# STM8TL53F4 register map
Vendor: STMicroelectronics; Series: STM8T; File version: 1.0
CPU: other r1p0, big endian, no MPU, no FPU, 4 interrupt priority bits
Registers are 8-bit, read-write, reset 0x0 unless marked. A register's access mark holds for its fields unless they carry their own. Offsets are from the block's base; [hi:lo] are bit positions; {n}, {i} and the like mark numbered series.

## PXS
Base 0x00005300
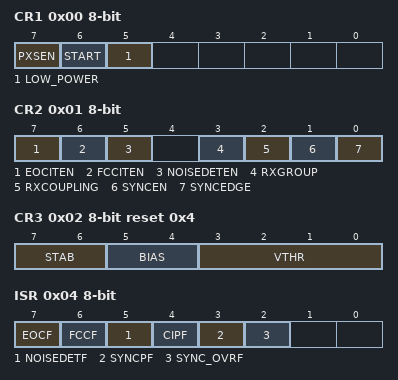
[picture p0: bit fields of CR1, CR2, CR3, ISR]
0x00 CR1 — ProxSense control register 1
  [7] PXSEN, [6] START, [5] LOW_POWER
0x01 CR2 — ProxSense control register 2
  [7] EOCITEN, [6] FCCITEN, [5] NOISEDETEN, [3] RXGROUP, [2] RXCOUPLING, [1] SYNCEN, [0] SYNCEDGE
0x02 CR3 reset 0x4 — ProxSense control register 3
  [7:6] STAB, [5:4] BIAS, [3:0] VTHR
0x04 ISR — ProxSense interrupt and status register
  [7] EOCF, [6] FCCF, [5] NOISEDETF, [4] CIPF, [3] SYNCPF, [2] SYNC_OVRF
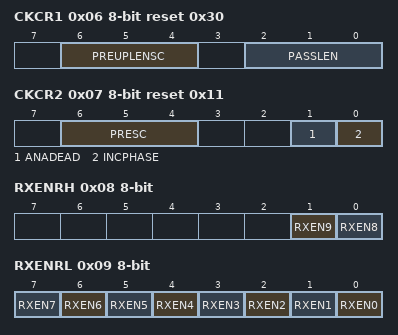
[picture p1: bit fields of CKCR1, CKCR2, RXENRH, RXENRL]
0x06 CKCR1 reset 0x30 — ProxSense clock control register 1
  [6:4] PREUPLENSC, [2:0] PASSLEN
0x07 CKCR2 reset 0x11 — ProxSense clock control register 2
  [6:4] PRESC, [1] ANADEAD, [0] INCPHASE
0x08 RXENRH — ProxSense receiver enable register high
  [1] RXEN9, [0] RXEN8
0x09 RXENRL — ProxSense receiver enable register low
  [n] RXEN{n} (n=0..7)
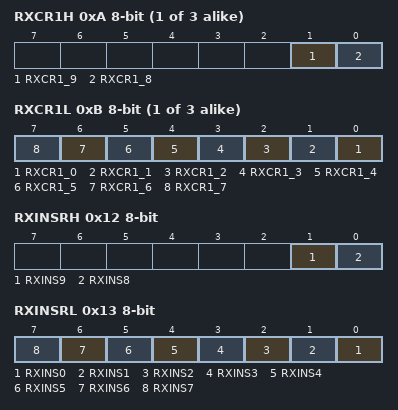
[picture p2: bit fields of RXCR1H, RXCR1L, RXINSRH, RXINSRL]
{0x8+2i} RXCR{i}H (i=1..3) — ProxSense receiver control register {i} high
  [1] RXCR{i}_9, [0] RXCR{i}_8
{0x9+2i} RXCR{i}L (i=1..3) — ProxSense receiver control register {i} low
  [n] RXCR{i}_{n} (n=0..7)
0x12 RXINSRH — ProxSense receiver inactive state register high
  [1] RXINS9, [0] RXINS8
0x13 RXINSRL — ProxSense receiver inactive state register low
  [n] RXINS{n} (n=0..7)
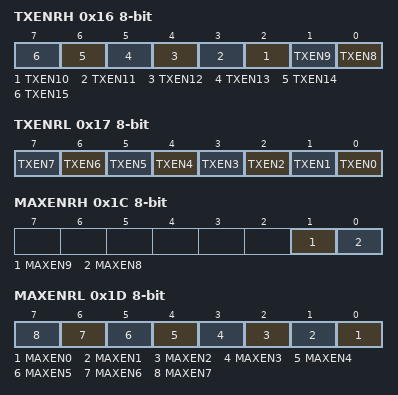
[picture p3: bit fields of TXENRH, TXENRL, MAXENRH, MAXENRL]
0x16 TXENRH — ProxSense transmit enable register high
  [n-8] TXEN{n} (n=8..15)
0x17 TXENRL — ProxSense transmit enable register low
  [n] TXEN{n} (n=0..7)
0x1A MAXRH reset 0xFF — ProxSense maximum counter value register high
  [7:0] MAX
0x1B MAXRL reset 0xFF — ProxSense maximum counter value register low
  [7:0] MAX
0x1C MAXENRH — ProxSense maximum counter enable register high
  [1] MAXEN9, [0] MAXEN8
0x1D MAXENRL — ProxSense maximum counter enable register low
  [n] MAXEN{n} (n=0..7)
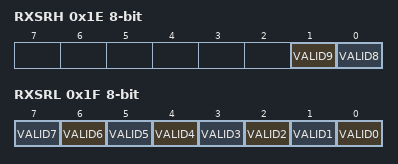
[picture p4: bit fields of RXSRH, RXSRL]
0x1E RXSRH — ProxSense receiver status register high
  [1] VALID9, [0] VALID8
0x1F RXSRL — ProxSense receiver status register low
  [n] VALID{n} (n=0..7)
{0x20+2i} RX{i}CNTRH (i=0..9) — ProxSense counter register receiver channel high
  [7:0] RX{i}CNT
{0x21+2i} RX{i}CNTRL (i=0..9) — ProxSense counter register receiver channel low
  [7:0] RX{i}CNT
{0x40+i} RX{i}CSSELR (i=0..9) — ProxSense receiver sampling capacitor selection register
  [4:0] RX{i}CSSEL
{0x50+i} RX{i}EPCCSELR (i=0..9) — ProxSense receiver electrode parasitic compensation capacitor selection register
  [7:0] RX{i}EPCC

## RST
Base 0x000050B0
0x00 CR — Reset control register
  [7:0] RSTPIN_KEY
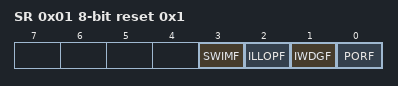
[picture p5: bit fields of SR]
0x01 SR reset 0x1 — Reset status register
  [3] SWIMF, [2] ILLOPF, [1] IWDGF, [0] PORF

## SPI
Base 0x00005200
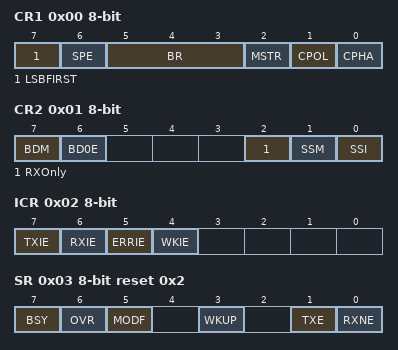
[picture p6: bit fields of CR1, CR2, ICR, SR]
0x00 CR1 — SPI control register 1
  [7] LSBFIRST, [6] SPE, [5:3] BR, [2] MSTR, [1] CPOL, [0] CPHA
0x01 CR2 — SPI control register 2
  [7] BDM, [6] BD0E, [2] RXOnly, [1] SSM, [0] SSI
0x02 ICR — SPI interrupt control register
  [7] TXIE, [6] RXIE, [5] ERRIE, [4] WKIE
0x03 SR reset 0x2 — SPI status register
  [7] BSY, [6] OVR, [5] MODF, [3] WKUP, [1] TXE, [0] RXNE
0x04 DR — SPI data register

## SWIM
Base 0x00007F80
0x00 CSR — SWIM control status register

## TIM2
Base 0x00005250
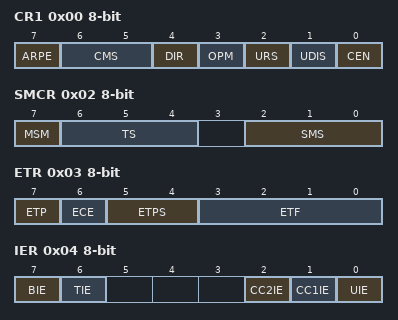
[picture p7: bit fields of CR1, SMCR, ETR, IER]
0x00 CR1 — TIM2 Control register 1
  [7] ARPE, [6:5] CMS, [4] DIR, [3] OPM, [2] URS, [1] UDIS, [0] CEN
0x01 CR2 — TIM2 Control register 2
  [6:4] MMS
0x02 SMCR — TIM2 Slave Mode Control register
  [7] MSM, [6:4] TS, [2:0] SMS
0x03 ETR — TIM2 external trigger register
  [7] ETP, [6] ECE, [5:4] ETPS, [3:0] ETF
0x04 IER — TIM2 Interrupt enable register
  [7] BIE, [6] TIE, [2] CC2IE, [1] CC1IE, [0] UIE
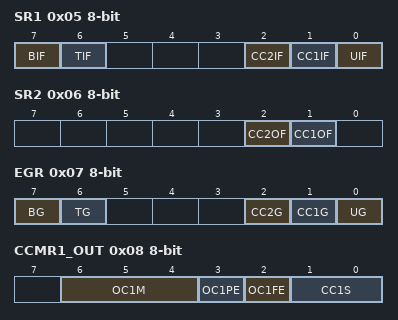
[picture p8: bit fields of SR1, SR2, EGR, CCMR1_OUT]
0x05 SR1 — TIM2 Status register 1
  [7] BIF, [6] TIF, [2] CC2IF, [1] CC1IF, [0] UIF
0x06 SR2 — TIM2 Status register 2
  [2] CC2OF, [1] CC1OF
0x07 EGR — TIM2 Event Generation register
  [7] BG, [6] TG, [2] CC2G, [1] CC1G, [0] UG
0x08 CCMR1_OUT — TIM2 Capture/Compare mode register 1
  [6:4] OC1M, [3] OC1PE, [2] OC1FE, [1:0] CC1S
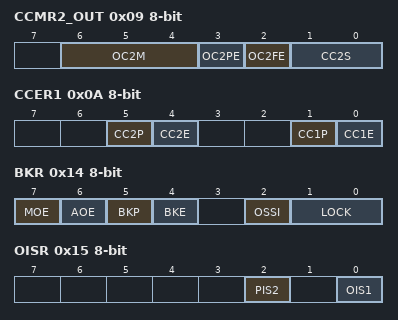
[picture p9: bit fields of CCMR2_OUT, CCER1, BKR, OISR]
0x09 CCMR2_OUT — TIM2 Capture/Compare mode register 2
  [6:4] OC2M, [3] OC2PE, [2] OC2FE, [1:0] CC2S
0x0A CCER1 — TIM2 Capture/Compare enable register 1
  [5] CC2P, [4] CC2E, [1] CC1P, [0] CC1E
0x0B CNTRH — TIM2 Counter high
  [7:0] CNT
0x0C CNTRL — TIM2 Counter low
  [7:0] CNT
0x0D PSCR — TIM2 Prescaler register
  [2:0] PSC
0x0E ARRH reset 0xFF — TIM2 Auto-reload register high
  [7:0] ARR
0x0F ARRL reset 0xFF — TIM2 Auto-reload register low
  [7:0] ARR
0x10 CCR1H — TIM2 Capture/Compare register 1 high
  [7:0] CCR
0x11 CCR1L — TIM2 Capture/Compare register 1 low
  [7:0] CCR
0x12 CCR2H — TIM2 Capture/Compare register 2 high
  [7:0] CCR2
0x13 CCR2L — TIM2 Capture/Compare register 2 low
  [7:0] CCR2
0x14 BKR — TIM2 Break register
  [7] MOE, [6] AOE, [5] BKP, [4] BKE, [2] OSSI, [1:0] LOCK
0x15 OISR — TIM2 Output idle state register
  [2] PIS2, [0] OIS1

## TIM3
Base 0x00005280
Registers as TIM2 (with TIM2 read as TIM3).

## TIM4
Base 0x000052E0
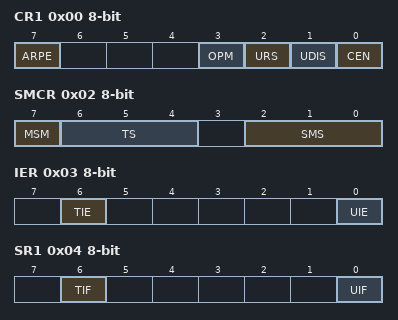
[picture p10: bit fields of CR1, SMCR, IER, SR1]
0x00 CR1 — TIM4 Control register 1
  [7] ARPE, [3] OPM, [2] URS, [1] UDIS, [0] CEN
0x01 CR2 — TIM4 Control register 2
  [6:4] MMS
0x02 SMCR — TIM4 Slave Mode Control Register
  [7] MSM, [6:4] TS, [2:0] SMS
0x03 IER — TIM4 Interrupt enable register
  [6] TIE, [0] UIE
0x04 SR1 — TIM4 Status register 1
  [6] TIF, [0] UIF
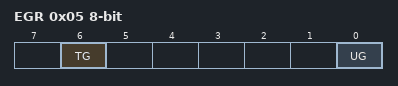
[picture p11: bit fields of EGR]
0x05 EGR — TIM4 Event Generation register
  [6] TG, [0] UG
0x06 CNTR — TIM4 Counter
  [7:0] CNT
0x07 PSCR — TIM4 Prescaler register
  [3:0] PSC
0x08 ARR reset 0xFF — TIM4 Auto-reload register low

## USART
Base 0x00005230
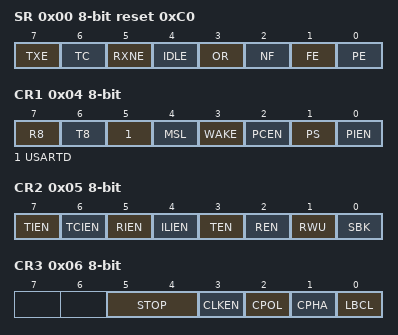
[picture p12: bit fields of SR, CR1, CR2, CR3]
0x00 SR reset 0xC0 — USART Status Register
  [7] TXE, [6] TC, [5] RXNE, [4] IDLE, [3] OR, [2] NF, [1] FE, [0] PE
0x01 DR — USART Data Register
0x02 BRR1 — USART Baud Rate Register 1
  [7:0] USART_DIV
0x03 BRR2 — USART Baud Rate Register 2
  [7:0] USART_DIV
0x04 CR1 — USART Control Register 1
  [7] R8, [6] T8, [5] USARTD, [4] MSL, [3] WAKE, [2] PCEN, [1] PS, [0] PIEN
0x05 CR2 — USART Control Register 2
  [7] TIEN, [6] TCIEN, [5] RIEN, [4] ILIEN, [3] TEN, [2] REN, [1] RWU, [0] SBK
0x06 CR3 — USART Control Register 3
  [5:4] STOP, [3] CLKEN, [2] CPOL, [1] CPHA, [0] LBCL
0x07 CR4 — USART Control Register 4
  [3:0] ADD

## WFE
Base 0x000050A6
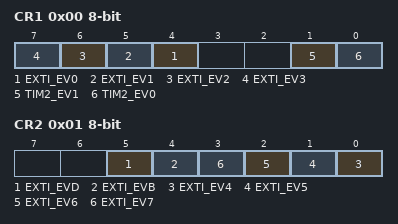
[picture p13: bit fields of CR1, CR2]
0x00 CR1 — WFE control register 1
  [n+4] EXTI_EV{n} (n=0..3), [1] TIM2_EV1, [0] TIM2_EV0
0x01 CR2 — WFE control register 2
  [5] EXTI_EVD, [4] EXTI_EVB, [n-4] EXTI_EV{n} (n=4..7)

## WDG
Base 0x000050D3
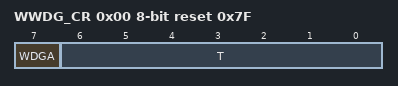
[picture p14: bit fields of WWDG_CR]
0x00 WWDG_CR reset 0x7F — WWDG control register
  [7] WDGA, [6:0] T
0x01 WWDG_WR reset 0x7F — WWDG window register
  [6:0] W
0x0D IWDG_KR — IWDG Key register
  [7:0] KEY
0x0E IWDG_PR — IWDG Prescaler register
  [2:0] PR
0x0F IWDG_RLR reset 0xFF — IWDG Reload register
  [7:0] RL
